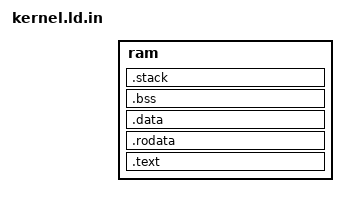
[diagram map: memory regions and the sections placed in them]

#include <kconfig.h>

ENTRY(_start)
EXTERN(_start)

MEMORY
{
  ram : ORIGIN = CONFIG_KERNEL_BASE, LENGTH = CONFIG_KERNEL_RAM_SIZE
}

SECTIONS
{
  .text : {
    __kernel_start = .;

    *(.text.start)
    *(.text)
  } > ram

  .rodata : {
    *(.rodata)
  } > ram

  .data : {
    *(.data)
  } > ram

  __bss_start = .;
  .bss : {
    *(.bss)
  } > ram
  __bss_end = .;

  .stack ALIGN(CONFIG_PAGE_SIZE) (NOLOAD) : {
    __boot_stack_bottom = .;
    . = CONFIG_BOOT_STACK_SIZE;
  } > ram
  __boot_stack_top = .;

  __kernel_end = .;
  __ram_end = ORIGIN(ram) + LENGTH(ram);
}
